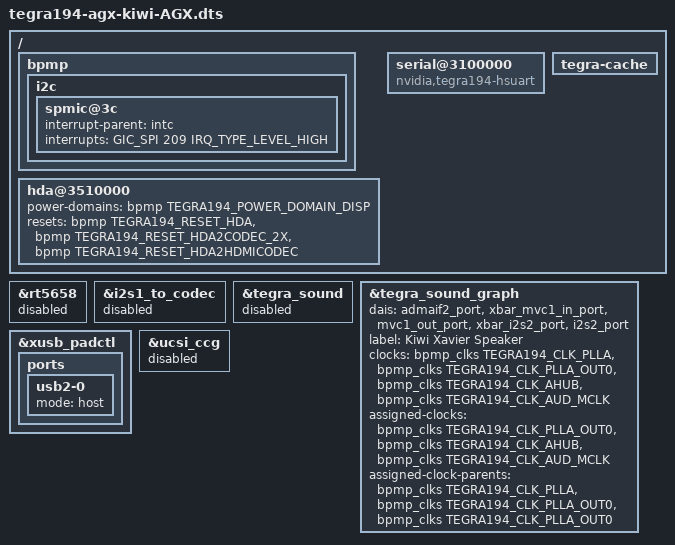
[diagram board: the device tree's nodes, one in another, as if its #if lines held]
/*
 * Top level DTS file for Kiwi carrier board (CVM:P2888-0001, CVB:P2822-0000).
 *
 * Board-variant of the stock Xavier AGX devkit dts, rebased onto the
 * current L4T 35.4.1 source (the previous kiwi dts was a ~2021-baseline
 * decompile, schema-mismatched against this kernel/RCE firmware — see
 * project memory [[project_jp5_rce_boot_hang]]). Kiwi shares the same
 * physical CVM/CVB as the reference devkit; the only confirmed hardware
 * delta is audio: kiwi drives a discrete I2S2 speaker amp directly
 * (via runtime AHUB routing, "I2S2 Mux"/"MVC1 Mux"/"MVC1 Vol"), not the
 * devkit's on-board RT5658 codec — that chip isn't present on this board.
 */
#include "common/tegra194-p2888-0001-p2822-0000-common.dtsi"
#include "common/tegra194-p2822-camera-modules.dtsi"
#include "common/tegra194-audio-p2822-0000.dtsi"

#if defined(LINUX_VERSION) && LINUX_VERSION >= 419

/ {
	/* FIXME: K5.4 overrides */
	bpmp {
		i2c {
			spmic@3c {
				interrupt-parent = <&intc>;
				interrupts = <GIC_SPI 209 IRQ_TYPE_LEVEL_HIGH>;
			};
		};
	};

	hda@3510000 {
		power-domains = <&bpmp TEGRA194_POWER_DOMAIN_DISP>;
		resets = <&bpmp TEGRA194_RESET_HDA>,
			 <&bpmp TEGRA194_RESET_HDA2CODEC_2X>,
			 <&bpmp TEGRA194_RESET_HDA2HDMICODEC>;
		reset-names = "hda", "hda2codec_2x", "hda2hdmi";
	};

	serial@3100000 {
		compatible = "nvidia,tegra194-hsuart";
	};

	tegra-cache {
		status = "okay";
	};
};

#endif

/*
 * Kiwi carrier board has no RT5658 codec on this i2c bus — disable it so
 * the "sound" (nvidia,tegra186-ape) card doesn't block registration
 * waiting on a codec component that will never probe successfully.
 */
&rt5658 {
	status = "disabled";
};

/* Drop the RT5658 dai-link along with the codec above; kiwi only needs
 * I2S2 (left at its tegra186-audio-dai-links.dtsi default: a dummy BE,
 * routed at runtime via amixer) for its discrete speaker amp. */
&i2s1_to_codec {
	status = "disabled";
};

/*
 * "sound" (compatible nvidia,tegra186-ape, tegra_machine_driver.c under
 * nvidia/sound/soc/tegra-alt) can NEVER probe on this 5.10 kernel: its
 * whole Kconfig menu (nvidia/sound/soc/tegra-alt/Kconfig) is only
 * `source`d by nvidia/sound/soc/Kconfig when kernel VERSION < 5 — dead
 * code path, confirmed zero CONFIG_SND_SOC_TEGRA_ALT* symbols anywhere
 * in .config. This is why aplay -l never showed an I2S card. Disable it
 * and use "sound_graph" (nvidia,tegra186-audio-graph-card -> mainline
 * sound/soc/tegra/tegra_audio_graph_card.c) instead, which IS reachable
 * (sound/soc/tegra/Kconfig is unconditionally sourced) and already
 * built as CONFIG_SND_SOC_TEGRA_AUDIO_GRAPH_CARD=m. Its i2s2_port is
 * wired to an I2S_DUMMY endpoint by default in tegra186-audio-graph.dtsi
 * — same dummy-BE speaker path kiwi already relies on, no rewiring
 * needed.
 */
&tegra_sound {
	status = "disabled";
};

/*
 * The stock "sound_graph" dais list wires in every AHUB block on the chip
 * (~150 ports: all ADMAIF/ADSP FE's, every XBAR accelerator, every BE) and
 * its routing/widgets tables are hardcoded to the devkit's RT5658 codec pin
 * names (CVB-RT ...), which never exist here since &rt5658 is disabled.
 * graph_parse_of() (sound/soc/generic/audio-graph-card.c) needs every listed
 * DAI to resolve or the whole card silently EPROBE_DEFERs forever — confirmed
 * on hw via /sys/kernel/debug/devices_deferred (sound_graph stuck there,
 * dyndbg unavailable on this kernel so root port not individually isolated).
 *
 * Kiwi doesn't do compile-time DAPM routing at all — the discrete I2S2 amp
 * is wired up at runtime via AHUB mux amixer commands (see
 * rover/balena_configs/configuration.sh interfacesConfiguration():
 * "I2S2 Mux"->MVC1, "MVC1 Mux"->ADMAIF2, "MVC1 Vol"), which is a DPCM
 * codec2codec chain: ADMAIF2 (FE) -> MVC1 (accelerator) -> I2S2 (BE, dummy
 * codec). Trim "dais" down to just that chain, and drop the stale
 * RT5658 routing/widgets — DPCM audio-graph mode doesn't need them, path
 * selection happens at runtime via the mux controls above, not DAPM routes.
 */
&tegra_sound_graph {
	status = "okay";

	dais = <&admaif2_port>,
	       <&xbar_mvc1_in_port>, <&mvc1_out_port>,
	       <&xbar_i2s2_port>, <&i2s2_port>;

	label = "Kiwi Xavier Speaker";

	/delete-property/ widgets;
	/delete-property/ routing;

	/*
	 * Stock only assigns AUD_MCLK's parent. The proven-working JP4 "sound"
	 * node (tegra-alt/tegra186ref) on this same board also explicitly locks
	 * AHUB's clock parent to PLLA_OUT0 (its "ahub"/"extern1" named clocks;
	 * "extern1" = AUD_MCLK's pre-T194 name, same clock id 7 either way) —
	 * without that, AHUB free-runs off its own default parent, which can
	 * leave the whole crossbar (I2S2/MVC1/ADMAIF) clocked out of spec even
	 * though ALSA sees a clean, underrun-free PCM stream. Match JP4 exactly.
	 */
	clocks = <&bpmp_clks TEGRA194_CLK_PLLA>,
		 <&bpmp_clks TEGRA194_CLK_PLLA_OUT0>,
		 <&bpmp_clks TEGRA194_CLK_AHUB>,
		 <&bpmp_clks TEGRA194_CLK_AUD_MCLK>;
	clock-names = "pll_a", "plla_out0", "ahub", "extern1";
	assigned-clocks = <&bpmp_clks TEGRA194_CLK_PLLA_OUT0>,
			  <&bpmp_clks TEGRA194_CLK_AHUB>,
			  <&bpmp_clks TEGRA194_CLK_AUD_MCLK>;
	assigned-clock-parents = <&bpmp_clks TEGRA194_CLK_PLLA>,
				  <&bpmp_clks TEGRA194_CLK_PLLA_OUT0>,
				  <&bpmp_clks TEGRA194_CLK_PLLA_OUT0>;
};

/*
 * USB: the Kiwi CM+ carrier wires all four USB2 pads as HOST ports (verified in the
 * working JP4 kiwi DTB: usb2-0..3 mode="host" with vbus supplies). The stock devkit
 * dtsi leaves usb2-0 as an OTG port with a role switch, so a camera plugged there
 * never enumerates and introspection.sh (which reads usb2-0/mode) misdetects the
 * board as a devkit. Force host mode and drop the OTG connector glue.
 */
&xusb_padctl {
	ports {
		usb2-0 {
			mode = "host";
			/delete-property/ usb-role-switch;
			/delete-node/ port;   /* OTG role-switch endpoint (usb_role_switch0), referenced by ucsi_ccg below */
		};
	};
};

/* The devkit's USB-C controller (Cypress CCG, i2c c240000 @0x08) is not on the Kiwi carrier
 * (dmesg: "ucsi_ccg 1-0008: i2c_transfer failed -121"). Disable it and drop its connector, whose
 * endpoint references the usb2-0 role-switch port removed above. */
&ucsi_ccg {
	status = "disabled";
	/delete-node/ connector@0;
};
